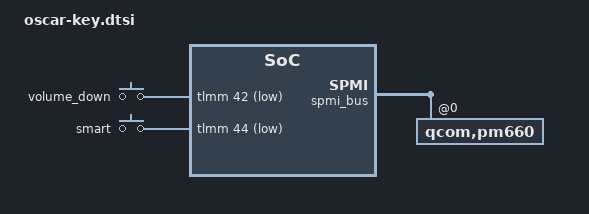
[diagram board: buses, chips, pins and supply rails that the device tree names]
/* Copyright (c) 2016-2017, The Linux Foundation. All rights reserved.
 *
 * This program is free software; you can redistribute it and/or modify
 * it under the terms of the GNU General Public License version 2 and
 * only version 2 as published by the Free Software Foundation.
 *
 * This program is distributed in the hope that it will be useful,
 * but WITHOUT ANY WARRANTY; without even the implied warranty of
 * MERCHANTABILITY or FITNESS FOR A PARTICULAR PURPOSE.  See the
 * GNU General Public License for more details.
 */


&spmi_bus {
	qcom,pm660@0 {
		qcom,power-on@800 {
			compatible = "qcom,qpnp-power-on";
			reg = <0x800 0x100>;

			/* PON 2 for VOL_UP */
			qcom,pon_2 {
				linux,code = <115>;
			};
		};
	};
};


&soc {
	gpio_keys {
		compatible = "gpio-keys";
		input-name = "gpio-keys";

		/* GPIO 42 for VOL_DN */
		vol_dn {
			label = "volume_down";
			gpios = <&tlmm 42 0x1>;
			linux,input-type = <1>;
			linux,code = <114>;
			gpio-key,wakeup;
			debounce-interval = <15>;
		};

		/* GPIO 44 for SMART */
		smart {
			label = "smart";
			gpios = <&tlmm 44 0x1>;
			linux,input-type = <1>;
			linux,code = <0x2fe>;
			gpio-key,wakeup;
			debounce-interval = <15>;
		};
	};
};
